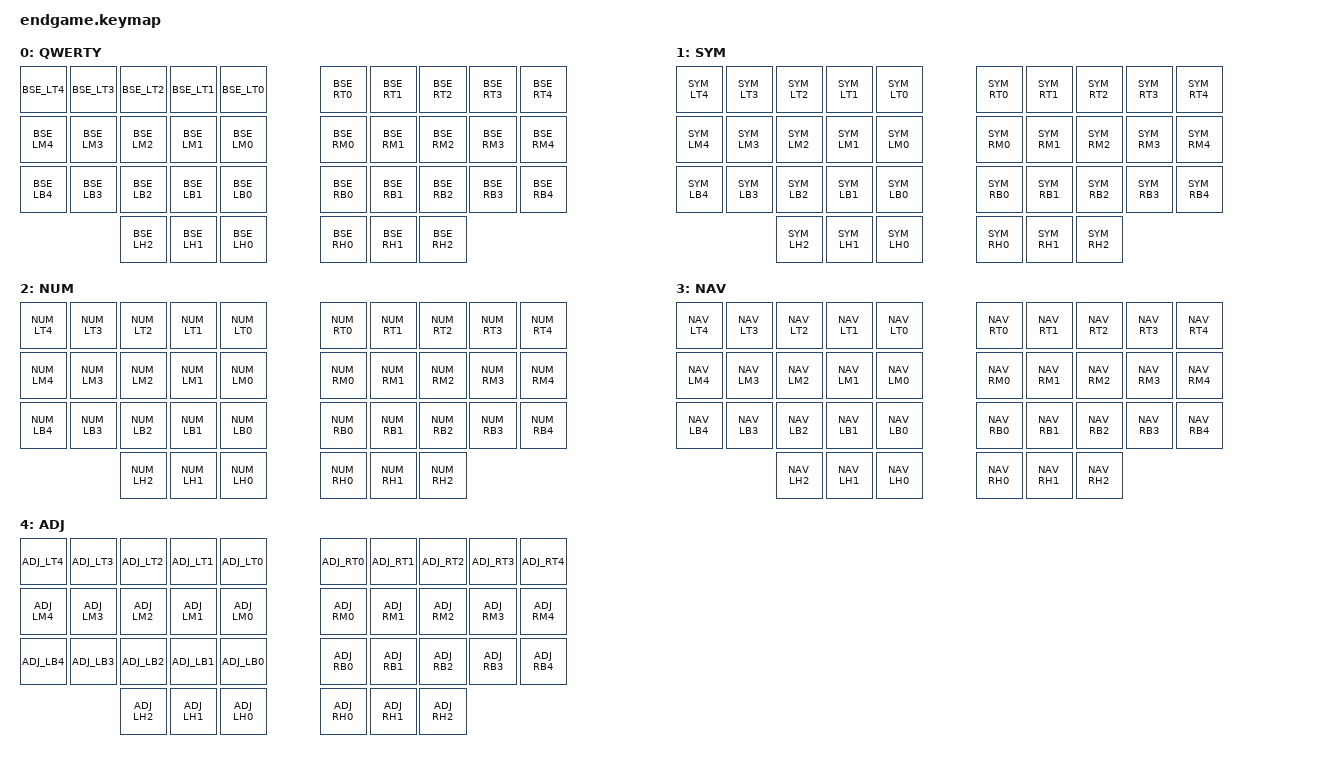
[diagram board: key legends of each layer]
#include <behaviors.dtsi>
#include <dt-bindings/zmk/keys.h>
#include <dt-bindings/zmk/bt.h>
#include <dt-bindings/zmk/outputs.h>
#include <dt-bindings/zmk/backlight.h>

#include "../../../headers/keypos/endgame.h"
#include "../../../headers/common/common.h"
#include "../../../headers/keymap/keymap.h"

/ {

    keymap {
        compatible = "zmk,keymap";

        qwerty {
            label = "QWERTY";
            bindings = <
                BSE_LT4 BSE_LT3 BSE_LT2 BSE_LT1 BSE_LT0 BSE_RT0 BSE_RT1 BSE_RT2 BSE_RT3 BSE_RT4
                BSE_LM4 BSE_LM3 BSE_LM2 BSE_LM1 BSE_LM0 BSE_RM0 BSE_RM1 BSE_RM2 BSE_RM3 BSE_RM4
                BSE_LB4 BSE_LB3 BSE_LB2 BSE_LB1 BSE_LB0 BSE_RB0 BSE_RB1 BSE_RB2 BSE_RB3 BSE_RB4
                BSE_LH2                 BSE_LH1 BSE_LH0 BSE_RH0 BSE_RH1                 BSE_RH2
            >;
        };

        symbols {
            label = "SYM";
            bindings = <
                SYM_LT4 SYM_LT3 SYM_LT2 SYM_LT1 SYM_LT0 SYM_RT0 SYM_RT1 SYM_RT2 SYM_RT3 SYM_RT4
                SYM_LM4 SYM_LM3 SYM_LM2 SYM_LM1 SYM_LM0 SYM_RM0 SYM_RM1 SYM_RM2 SYM_RM3 SYM_RM4
                SYM_LB4 SYM_LB3 SYM_LB2 SYM_LB1 SYM_LB0 SYM_RB0 SYM_RB1 SYM_RB2 SYM_RB3 SYM_RB4
                SYM_LH2                 SYM_LH1 SYM_LH0 SYM_RH0 SYM_RH1                 SYM_RH2
            >;
        };

        numbers {
            label = "NUM";
            bindings = <
                NUM_LT4 NUM_LT3 NUM_LT2 NUM_LT1 NUM_LT0 NUM_RT0 NUM_RT1 NUM_RT2 NUM_RT3 NUM_RT4
                NUM_LM4 NUM_LM3 NUM_LM2 NUM_LM1 NUM_LM0 NUM_RM0 NUM_RM1 NUM_RM2 NUM_RM3 NUM_RM4
                NUM_LB4 NUM_LB3 NUM_LB2 NUM_LB1 NUM_LB0 NUM_RB0 NUM_RB1 NUM_RB2 NUM_RB3 NUM_RB4
                NUM_LH2                 NUM_LH1 NUM_LH0 NUM_RH0 NUM_RH1                 NUM_RH2
            >;
        };

        navigation {
            label = "NAV";

            bindings = <
                NAV_LT4 NAV_LT3 NAV_LT2 NAV_LT1 NAV_LT0 NAV_RT0 NAV_RT1 NAV_RT2 NAV_RT3 NAV_RT4
                NAV_LM4 NAV_LM3 NAV_LM2 NAV_LM1 NAV_LM0 NAV_RM0 NAV_RM1 NAV_RM2 NAV_RM3 NAV_RM4
                NAV_LB4 NAV_LB3 NAV_LB2 NAV_LB1 NAV_LB0 NAV_RB0 NAV_RB1 NAV_RB2 NAV_RB3 NAV_RB4
                NAV_LH2                 NAV_LH1 NAV_LH0 NAV_RH0 NAV_RH1                 NAV_RH2
            >;
        };

        adjust {
            label = "ADJ";

            bindings = <
                ADJ_LT4 ADJ_LT3 ADJ_LT2 ADJ_LT1 ADJ_LT0 ADJ_RT0 ADJ_RT1 ADJ_RT2 ADJ_RT3 ADJ_RT4
                ADJ_LM4 ADJ_LM3 ADJ_LM2 ADJ_LM1 ADJ_LM0 ADJ_RM0 ADJ_RM1 ADJ_RM2 ADJ_RM3 ADJ_RM4
                ADJ_LB4 ADJ_LB3 ADJ_LB2 ADJ_LB1 ADJ_LB0 ADJ_RB0 ADJ_RB1 ADJ_RB2 ADJ_RB3 ADJ_RB4
                ADJ_LH2                 ADJ_LH1 ADJ_LH0 ADJ_RH0 ADJ_RH1                 ADJ_RH2
            >;
        };
    };
};
